# GD32F30x_XD register map
File version: 1.0
CPU: CM4 r2p1, little endian, MPU, FPU, 4 interrupt priority bits
Registers are 32-bit, read-write, reset 0x0 unless marked. A register's access mark holds for its fields unless they carry their own. Offsets are from the block's base; [hi:lo] are bit positions; {n}, {i} and the like mark numbered series.

## BKP — Backup registers
Base 0x40006C00
{0x4+4i} DATA{i} 16-bit (i=0..9) — Backup data register {i}
  [15:0] DATA — Backup data
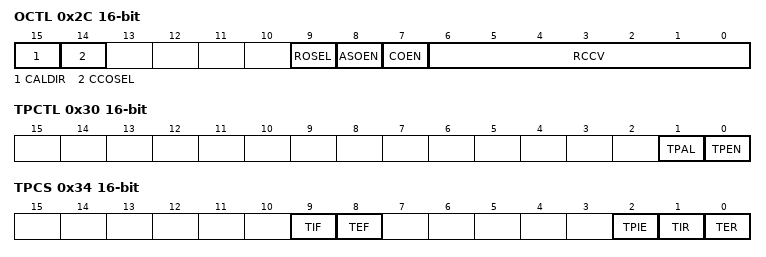
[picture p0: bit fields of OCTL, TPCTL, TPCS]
0x2C OCTL 16-bit — RTC signal output control register
  [15] CALDIR — RTC clock calibration direction
  [14] CCOSEL — RTC clock output selection
  [9] ROSEL — RTC output selection
  [8] ASOEN — RTC alarm or second signal output enable
  [7] COEN — RTC clock calibration output enable
  [6:0] RCCV — RTC clock calibration value
0x30 TPCTL 16-bit — Tamper pin control register
  [1] TPAL — TAMPER pin active level
  [0] TPEN — TAMPER detection enable
0x34 TPCS 16-bit — Tamper control and status register
  [9] TIF — Tamper interrupt flag
  [8] TEF — Tamper event flag
  [2] TPIE — Tamper interrupt enable
  [1] TIR — Tamper interrupt reset
  [0] TER — Tamper event reset
{0x18+4i} DATA{i} 16-bit (i=10..41) — Backup data register {i}
  [15:0] DATA — Backup data

## CRC — cyclic redundancy check calculation unit
Base 0x40023000
0x00 DATA reset 0xFFFFFFFF
  [31:0] DATA — CRC calculation result bits
0x04 FDATA — Free data register
  [7:0] FDATA — Free Data Register bits
0x08 CTL — Control register
  [0] RST — reset bit

## CTC — Clock trim controller
Base 0x4000C800
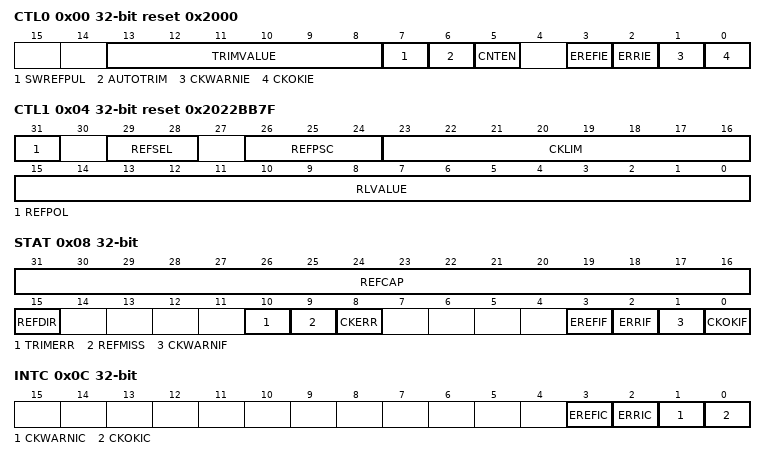
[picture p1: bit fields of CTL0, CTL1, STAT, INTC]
0x00 CTL0 reset 0x2000 — Control register 0
  [13:8] TRIMVALUE — IRC48M trim value
  [7] SWREFPUL — Software reference source sync pulse
  [6] AUTOTRIM — Hardware automatically trim mode
  [5] CNTEN — CTC counter enable
  [3] EREFIE — EREFIF interrupt enable
  [2] ERRIE — Error interrupt enable
  [1] CKWARNIE — Clock trim warning interrupt enable
  [0] CKOKIE — Clock trim ok interrupt enable
0x04 CTL1 reset 0x2022BB7F — Control register 1
  [31] REFPOL — Reference signal source polarity
  [29:28] REFSEL — Reference signal source selection
  [26:24] REFPSC — Reference signal source prescaler
  [23:16] CKLIM — Clock trim base limit value
  [15:0] RLVALUE — CTC counter reload value
0x08 STAT ro — Status register
  [31:16] REFCAP — CTC counter capture when reference sync pulse
  [15] REFDIR — CTC trim counter direction when reference sync pulse
  [10] TRIMERR — Trim value error bit
  [9] REFMISS — Reference sync pulse miss
  [8] CKERR — Clock trim error bit
  [3] EREFIF — Expect reference interrupt flag
  [2] ERRIF — Error interrupt flag
  [1] CKWARNIF — Clock trim warning interrupt flag
  [0] CKOKIF — Clock trim OK interrupt flag
0x0C INTC wo — Interrupt clear register
  [3] EREFIC — EREFIF interrupt clear bit
  [2] ERRIC — ERRIF interrupt clear bit
  [1] CKWARNIC — CKWARNIF interrupt clear bit
  [0] CKOKIC — CKOKIF interrupt clear bit

## DAC — Digital-to-analog converter
Base 0x40007400
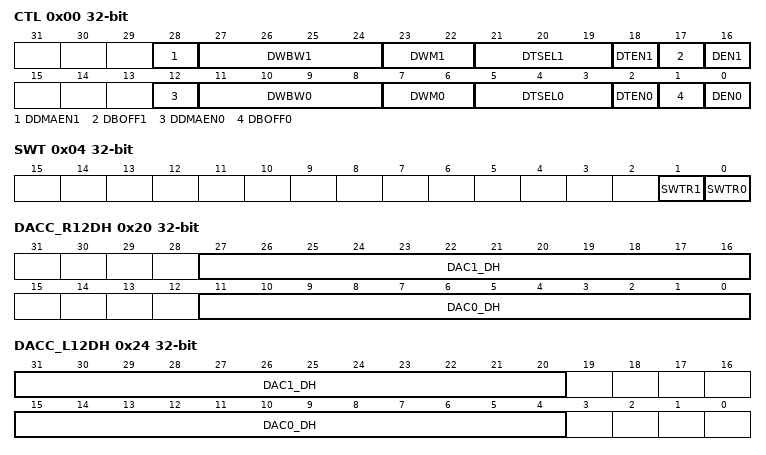
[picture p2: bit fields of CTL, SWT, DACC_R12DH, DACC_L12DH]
0x00 CTL — control register
  [28] DDMAEN1 — DAC1 DMA enable
  [27:24] DWBW1 — DAC1 noise wave bit width
  [23:22] DWM1 — DAC1 noise wave mode
  [21:19] DTSEL1 — DAC1 trigger selection
  [18] DTEN1 — DAC1 trigger enable
  [17] DBOFF1 — DAC1 output buffer turn off
  [16] DEN1 — DAC1 enable
  [12] DDMAEN0 — DAC0 DMA enable
  [11:8] DWBW0 — DAC0 noise wave bit width
  [7:6] DWM0 — DAC0 noise wave mode
  [5:3] DTSEL0 — DAC0 trigger selection
  [2] DTEN0 — DAC0 trigger enable
  [1] DBOFF0 — DAC0 output buffer turn off
  [0] DEN0 — DAC0 enable
0x04 SWT wo — software trigger register
  [1] SWTR1 — DAC1 software trigger
  [0] SWTR0 — DAC0 software trigger
0x08 DAC0_R12DH — DAC0 12-bit right-aligned data holding register
  [11:0] DAC0_DH — DAC0 12-bit right-aligned data
0x0C DAC0_L12DH — DAC0 12-bit left-aligned data holding register
  [15:4] DAC0_DH — DAC0 12-bit left-aligned data
0x10 DAC0_R8DH — DAC0 8-bit right aligned data holding register
  [7:0] DAC0_DH — DAC0 8-bit right-aligned data
0x14 DAC1_R12DH — DAC1 12-bit right-aligned data holding register
  [11:0] DAC1_DH — DAC1 12-bit right-aligned data
0x18 DAC1_L12DH — DAC1 12-bit left aligned data holding register
  [15:4] DAC1_DH — DAC1 12-bit left-aligned data
0x1C DAC1_R8DH — DAC1 8-bit right aligned data holding register
  [7:0] DAC1_DH — DAC1 8-bit right-aligned data
0x20 DACC_R12DH — DAC concurrent mode 12-bit right-aligned data holding register
  [27:16] DAC1_DH — DAC1 12-bit right-aligned data
  [11:0] DAC0_DH — DAC0 12-bit right-aligned data
0x24 DACC_L12DH — DAC concurrent mode 12-bit left aligned data holding register
  [31:20] DAC1_DH — DAC1 12-bit left-aligned data
  [15:4] DAC0_DH — DAC0 12-bit left-aligned data
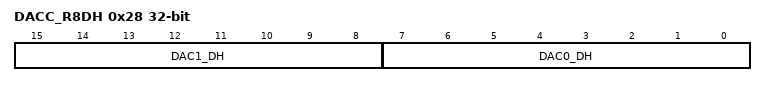
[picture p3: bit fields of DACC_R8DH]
0x28 DACC_R8DH — DAC concurrent mode 8-bit right aligned data holding register
  [15:8] DAC1_DH — DAC1 8-bit right-aligned data
  [7:0] DAC0_DH — DAC0 8-bit right-aligned data
0x2C DAC0_DO ro — DAC0 data output register
  [11:0] DAC0_DO — DAC0 data output
0x30 DAC1_DO ro — DAC1 data output register
  [11:0] DAC1_DO — DAC1 data output
